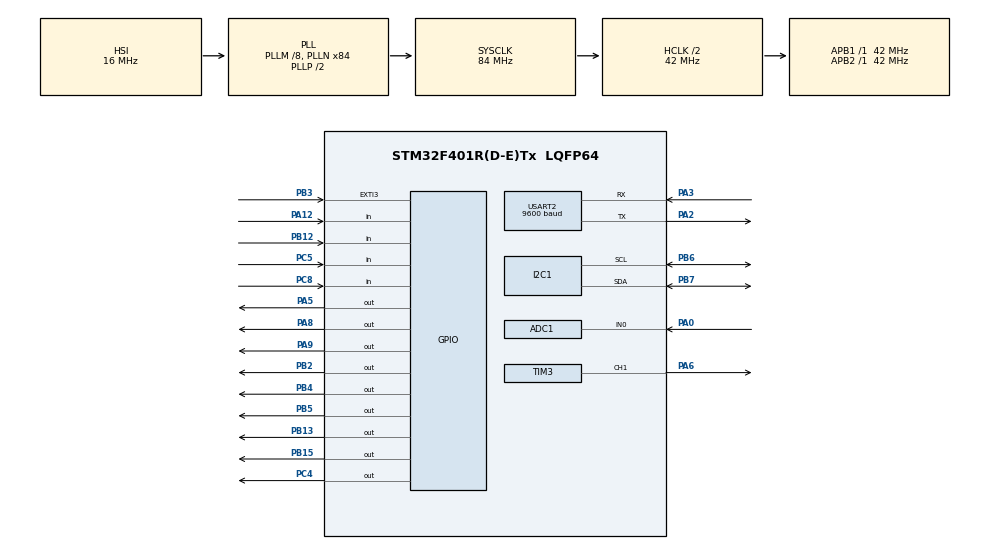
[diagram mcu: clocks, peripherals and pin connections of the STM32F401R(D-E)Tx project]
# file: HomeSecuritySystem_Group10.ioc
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ADC1.Channel-0\#ChannelRegularConversion=ADC_CHANNEL_0
ADC1.ContinuousConvMode=DISABLE
ADC1.DMAContinuousRequests=ENABLE
ADC1.NbrOfConversion=1
ADC1.NbrOfConversionFlag=1
ADC1.Rank-0\#ChannelRegularConversion=1
ADC1.SamplingTime-0\#ChannelRegularConversion=ADC_SAMPLETIME_3CYCLES
ADC1.master=1
Dma.ADC1.2.Direction=DMA_PERIPH_TO_MEMORY
Dma.ADC1.2.FIFOMode=DMA_FIFOMODE_DISABLE
Dma.ADC1.2.Instance=DMA2_Stream0
Dma.ADC1.2.MemDataAlignment=DMA_MDATAALIGN_HALFWORD
Dma.ADC1.2.MemInc=DMA_MINC_ENABLE
Dma.ADC1.2.Mode=DMA_NORMAL
Dma.ADC1.2.PeriphDataAlignment=DMA_PDATAALIGN_HALFWORD
Dma.ADC1.2.PeriphInc=DMA_PINC_DISABLE
Dma.ADC1.2.Priority=DMA_PRIORITY_LOW
Dma.I2C1_RX.1.Direction=DMA_PERIPH_TO_MEMORY
Dma.I2C1_RX.1.FIFOMode=DMA_FIFOMODE_DISABLE
Dma.I2C1_RX.1.Instance=DMA1_Stream0
Dma.I2C1_RX.1.MemDataAlignment=DMA_MDATAALIGN_BYTE
Dma.I2C1_RX.1.MemInc=DMA_MINC_ENABLE
Dma.I2C1_RX.1.Mode=DMA_NORMAL
Dma.I2C1_RX.1.PeriphDataAlignment=DMA_PDATAALIGN_BYTE
Dma.I2C1_RX.1.PeriphInc=DMA_PINC_DISABLE
Dma.I2C1_RX.1.Priority=DMA_PRIORITY_LOW
Dma.Request0=USART2_TX
Dma.Request1=I2C1_RX
Dma.Request2=ADC1
Dma.USART2_TX.0.Direction=DMA_MEMORY_TO_PERIPH
Dma.USART2_TX.0.FIFOMode=DMA_FIFOMODE_DISABLE
Dma.USART2_TX.0.Instance=DMA1_Stream6
Dma.USART2_TX.0.MemDataAlignment=DMA_MDATAALIGN_BYTE
Dma.USART2_TX.0.MemInc=DMA_MINC_ENABLE
Dma.USART2_TX.0.Mode=DMA_NORMAL
Dma.USART2_TX.0.PeriphDataAlignment=DMA_PDATAALIGN_BYTE
Dma.USART2_TX.0.PeriphInc=DMA_PINC_DISABLE
Dma.USART2_TX.0.Priority=DMA_PRIORITY_LOW
Mcu.Family=STM32F4
Mcu.Name=STM32F401R(D-E)Tx
Mcu.Package=LQFP64
NVIC.ADC_IRQn=true\:0\:0\:false\:false\:true\:true\:true
NVIC.DMA1_Stream0_IRQn=true\:0\:0\:false\:false\:true\:false\:true
NVIC.DMA1_Stream6_IRQn=true\:0\:0\:false\:false\:true\:false\:true
NVIC.DMA2_Stream0_IRQn=true\:0\:0\:false\:false\:true\:false\:true
NVIC.EXTI3_IRQn=true\:0\:0\:false\:false\:true\:true\:true
NVIC.I2C1_EV_IRQn=true\:0\:0\:false\:false\:true\:true\:true
NVIC.PriorityGroup=NVIC_PRIORITYGROUP_4
NVIC.TIM1_BRK_TIM9_IRQn=true\:0\:0\:false\:false\:true\:true\:true
NVIC.TIM1_TRG_COM_TIM11_IRQn=true\:0\:0\:false\:false\:true\:true\:true
NVIC.TIM1_UP_TIM10_IRQn=true\:0\:0\:false\:false\:true\:true\:true
NVIC.TIM3_IRQn=true\:0\:0\:false\:false\:true\:true\:true
NVIC.TIM4_IRQn=true\:0\:0\:false\:false\:true\:true\:true
NVIC.TIM5_IRQn=true\:0\:0\:false\:false\:true\:true\:true
NVIC.USART2_IRQn=true\:0\:0\:false\:false\:true\:true\:true
PA0-WKUP.Signal=ADCx_IN0
PA12.GPIO_PuPd=GPIO_PULLUP
PA12.Signal=GPIO_Input
PA2.Mode=Asynchronous
PA2.Signal=USART2_TX
PA3.Mode=Asynchronous
PA3.Signal=USART2_RX
PA5.Signal=GPIO_Output
PA6.Signal=S_TIM3_CH1
PA8.Signal=GPIO_Output
PA9.Signal=GPIO_Output
PB12.GPIO_PuPd=GPIO_PULLUP
PB12.Signal=GPIO_Input
PB13.Signal=GPIO_Output
PB15.Signal=GPIO_Output
PB2.Signal=GPIO_Output
PB3.Signal=GPXTI3
PB4.Signal=GPIO_Output
PB5.Signal=GPIO_Output
PB6.Mode=I2C
PB6.Signal=I2C1_SCL
PB7.Mode=I2C
PB7.Signal=I2C1_SDA
PC4.Signal=GPIO_Output
PC5.GPIO_PuPd=GPIO_PULLUP
PC5.Signal=GPIO_Input
PC8.GPIO_PuPd=GPIO_PULLUP
PC8.Signal=GPIO_Input
ProjectManager.HeapSize=0x200
ProjectManager.StackSize=0x400
ProjectManager.TargetToolchain=STM32CubeIDE
RCC.48MHZClocksFreq_Value=42000000
RCC.AHBCLKDivider=RCC_SYSCLK_DIV2
RCC.AHBFreq_Value=42000000
RCC.APB1Freq_Value=42000000
RCC.APB1TimFreq_Value=42000000
RCC.APB2Freq_Value=42000000
RCC.APB2TimFreq_Value=42000000
RCC.CortexFreq_Value=42000000
RCC.HCLKFreq_Value=42000000
RCC.HSE_VALUE=25000000
RCC.HSI_VALUE=16000000
RCC.LSE_VALUE=32768
RCC.PLLM=8
RCC.PLLN=84
RCC.SYSCLKFreq_VALUE=84000000
RCC.SYSCLKSource=RCC_SYSCLKSOURCE_PLLCLK
RCC.VCOOutputFreq_Value=168000000
SH.ADCx_IN0.0=ADC1_IN0,IN0
SH.S_TIM3_CH1.0=TIM3_CH1,PWM Generation1 CH1
TIM3.Channel-PWM\ Generation1\ CH1=TIM_CHANNEL_1
USART2.BaudRate=9600
USART2.VirtualMode=VM_ASYNC
VP_TIM10_VS_ClockSourceINT.Mode=Enable_Timer
VP_TIM11_VS_ClockSourceINT.Mode=Enable_Timer
VP_TIM3_VS_ClockSourceINT.Mode=Internal
VP_TIM4_VS_ClockSourceINT.Mode=Internal
VP_TIM5_VS_ClockSourceINT.Mode=Internal
VP_TIM9_VS_ClockSourceINT.Mode=Internal
board=custom

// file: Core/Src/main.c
/* USER CODE BEGIN Header */
/**
 ******************************************************************************
 * @file           : main.c
 * @brief          : Main program body
 ******************************************************************************
 * @attention
 *
 * <h2><center>&copy; Copyright (c) 2020 STMicroelectronics.
 * All rights reserved.</center></h2>
 *
 * This software component is licensed by ST under BSD 3-Clause license,
 * the "License"; You may not use this file except in compliance with the
 * License. You may obtain a copy of the License at:
 *                        opensource.org/licenses/BSD-3-Clause
 *
 ******************************************************************************
 */
/* USER CODE END Header */

#include <stdbool.h>
#include "main.h"
#include "adc.h"
#include "dma.h"
#include "i2c.h"
#include "tim.h"
#include "usart.h"
#include "gpio.h"
#include "procedure.h"
#include "ds1307rtc.h"
#include "keypad.h"
#include "configuration.h"

extern bool keypad_active;

void SystemClock_Config(void);
void peripherals_init(void);

int main(void)
{

  /* MCU Configuration--------------------------------------------------------*/

  /* Reset of all peripherals, Initializes the Flash interface and the Systick. */
  HAL_Init();

  /* Configure the system clock */
  SystemClock_Config();
  peripherals_init();

  /* USER CODE BEGIN 2 */

	HAL_TIM_Base_Start_IT(&htim10);
	user_configuration();
  /* USER CODE END 2 */

  /* Infinite loop */
	while (1) {
		if(keypad_active)
			start_sequence();
	}
}

void peripherals_init(void){
	/* Initialize all configured peripherals */
	  MX_GPIO_Init();
	  MX_DMA_Init();
	  MX_ADC1_Init();
	  MX_I2C1_Init();
	  MX_TIM5_Init();
	  MX_TIM9_Init();
	  MX_TIM10_Init();
	  MX_TIM11_Init();
	  MX_USART2_UART_Init();
	  MX_TIM3_Init();
	  MX_TIM4_Init();
	  ds1307rtc_init();
}
void SystemClock_Config(void)
{
  RCC_OscInitTypeDef RCC_OscInitStruct = {0};
  RCC_ClkInitTypeDef RCC_ClkInitStruct = {0};

  /** Configure the main internal regulator output voltage
  */
  __HAL_RCC_PWR_CLK_ENABLE();
  __HAL_PWR_VOLTAGESCALING_CONFIG(PWR_REGULATOR_VOLTAGE_SCALE2);
  /** Initializes the CPU, AHB and APB busses clocks
  */
  RCC_OscInitStruct.OscillatorType = RCC_OSCILLATORTYPE_HSI;
  RCC_OscInitStruct.HSIState = RCC_HSI_ON;
  RCC_OscInitStruct.HSICalibrationValue = RCC_HSICALIBRATION_DEFAULT;
  RCC_OscInitStruct.PLL.PLLState = RCC_PLL_ON;
  RCC_OscInitStruct.PLL.PLLSource = RCC_PLLSOURCE_HSI;
  RCC_OscInitStruct.PLL.PLLM = 8;
  RCC_OscInitStruct.PLL.PLLN = 84;
  RCC_OscInitStruct.PLL.PLLP = RCC_PLLP_DIV2;
  RCC_OscInitStruct.PLL.PLLQ = 4;
  if (HAL_RCC_OscConfig(&RCC_OscInitStruct) != HAL_OK)
  {
    Error_Handler();
  }
  /** Initializes the CPU, AHB and APB busses clocks
  */
  RCC_ClkInitStruct.ClockType = RCC_CLOCKTYPE_HCLK|RCC_CLOCKTYPE_SYSCLK
                              |RCC_CLOCKTYPE_PCLK1|RCC_CLOCKTYPE_PCLK2;
  RCC_ClkInitStruct.SYSCLKSource = RCC_SYSCLKSOURCE_PLLCLK;
  RCC_ClkInitStruct.AHBCLKDivider = RCC_SYSCLK_DIV2;
  RCC_ClkInitStruct.APB1CLKDivider = RCC_HCLK_DIV1;
  RCC_ClkInitStruct.APB2CLKDivider = RCC_HCLK_DIV1;

  if (HAL_RCC_ClockConfig(&RCC_ClkInitStruct, FLASH_LATENCY_1) != HAL_OK)
  {
    Error_Handler();
  }
}

void Error_Handler(void)
{
}

/************************ (C) COPYRIGHT STMicroelectronics *****END OF FILE****/
